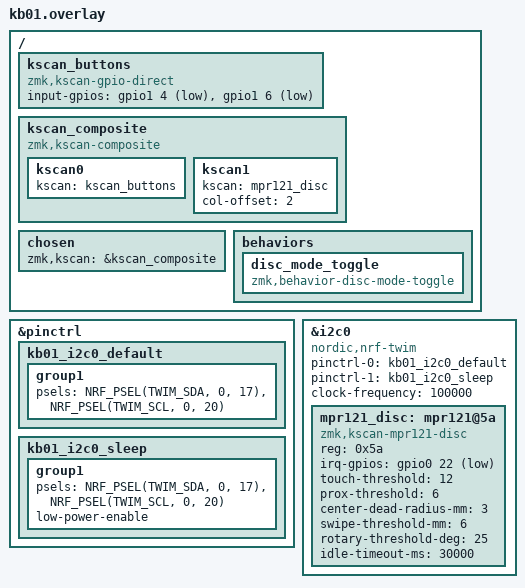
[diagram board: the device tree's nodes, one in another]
#include <zephyr/dt-bindings/gpio/gpio.h>
#include <zephyr/dt-bindings/pinctrl/nrf-pinctrl.h>

/ {
	/* 1. Standard ZMK direct GPIO scanning for the two physical buttons */
	kscan_buttons: kscan_buttons {
		compatible = "zmk,kscan-gpio-direct";
		input-gpios = <&gpio1 4 (GPIO_ACTIVE_LOW | GPIO_PULL_UP)>,
			      <&gpio1 6 (GPIO_ACTIVE_LOW | GPIO_PULL_UP)>;
	};

	/* 2. Merge the physical buttons and the MPR121 Disc into one matrix */
	kscan_composite: kscan_composite {
		compatible = "zmk,kscan-composite";
		
		kscan0 {
			kscan = <&kscan_buttons>;
			/* Buttons will be positions 0 and 1 */
		};
		
		kscan1 {
			kscan = <&mpr121_disc>;
			col-offset = <2>; 
			/* Disc gestures will be positions 2 through 21 */
		};
	};

	chosen {
		zmk,kscan = &kscan_composite;
	};

	behaviors {
		disc_mode_toggle: disc_mode_toggle {
			compatible = "zmk,behavior-disc-mode-toggle";
			#binding-cells = <0>;
		};
	};
};

&pinctrl {
	kb01_i2c0_default: kb01_i2c0_default {
		group1 {
			psels = <NRF_PSEL(TWIM_SDA, 0, 17)>,
				<NRF_PSEL(TWIM_SCL, 0, 20)>;
		};
	};

	kb01_i2c0_sleep: kb01_i2c0_sleep {
		group1 {
			psels = <NRF_PSEL(TWIM_SDA, 0, 17)>,
				<NRF_PSEL(TWIM_SCL, 0, 20)>;
			low-power-enable;
		};
	};
};

&i2c0 {
	status = "okay";
	compatible = "nordic,nrf-twim";
	pinctrl-0 = <&kb01_i2c0_default>;
	pinctrl-1 = <&kb01_i2c0_sleep>;
	pinctrl-names = "default", "sleep";
	clock-frequency = <100000>;

	mpr121_disc: mpr121@5a {
		compatible = "zmk,kscan-mpr121-disc";
		reg = <0x5a>;

		irq-gpios = <&gpio0 22 (GPIO_ACTIVE_LOW | GPIO_PULL_UP)>;

		touch-threshold = <12>;
		prox-threshold = <6>;
		center-dead-radius-mm = <3>;
		swipe-threshold-mm = <6>;
		rotary-threshold-deg = <25>;
		idle-timeout-ms = <30000>;
	};
};
